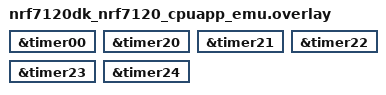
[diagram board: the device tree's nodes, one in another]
&timer00 {
	status = "okay";
};

// Timer 10 not working on the board, will be fixed in the future
// &timer10 {
//	status = "okay";
// };

&timer20 {
	status = "okay";
};

&timer21 {
	status = "okay";
};

&timer22 {
	status = "okay";
};

&timer23 {
	status = "okay";
};

&timer24 {
	status = "okay";
};
